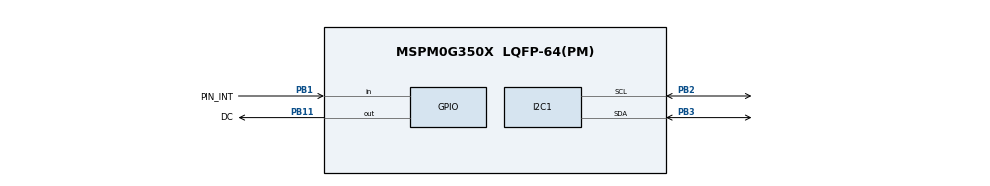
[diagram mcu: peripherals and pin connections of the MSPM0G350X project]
/**
 * @cliArgs --device "MSPM0G350X" --part "Default" --package "LQFP-64(PM)" --product "mspm0_sdk@2.05.01.00"
 * @versions {"tool":"1.24.1+4189"}
 */

/**
 * Import the modules used in this configuration.
 */
const GPIO   = scripting.addModule("/ti/driverlib/GPIO", {}, false);
const GPIO1  = GPIO.addInstance();
const GPIO2  = GPIO.addInstance();
const GPIO3  = GPIO.addInstance();
const I2C    = scripting.addModule("/ti/driverlib/I2C", {}, false);
const I2C1   = I2C.addInstance();
const SYSCTL = scripting.addModule("/ti/driverlib/SYSCTL");

/**
 * Write custom configuration values to the imported modules.
 */
GPIO1.$name                          = "GPIO_OLED";
GPIO1.port                           = "PORTB";
GPIO1.associatedPins.create(5);
GPIO1.associatedPins[0].$name        = "DC";
GPIO1.associatedPins[0].initialValue = "SET";
GPIO1.associatedPins[0].assignedPin  = "11";
GPIO1.associatedPins[0].pin.$assign  = "PB11";
GPIO1.associatedPins[1].$name        = "CS";
GPIO1.associatedPins[1].initialValue = "SET";
GPIO1.associatedPins[1].assignedPin  = "14";
GPIO1.associatedPins[2].$name        = "RST";
GPIO1.associatedPins[2].initialValue = "SET";
GPIO1.associatedPins[2].assignedPin  = "10";
GPIO1.associatedPins[3].initialValue = "SET";
GPIO1.associatedPins[3].assignedPin  = "9";
GPIO1.associatedPins[3].$name        = "SCL_OLED";
GPIO1.associatedPins[4].initialValue = "SET";
GPIO1.associatedPins[4].assignedPin  = "8";
GPIO1.associatedPins[4].$name        = "SDA_OLED";

const Board = scripting.addModule("/ti/driverlib/Board", {}, false);

GPIO2.$name                               = "GPIO_MPU6050";
GPIO2.port                                = "PORTB";
GPIO2.associatedPins[0].$name             = "PIN_INT";
GPIO2.associatedPins[0].direction         = "INPUT";
GPIO2.associatedPins[0].internalResistor  = "PULL_UP";
GPIO2.associatedPins[0].interruptEn       = true;
GPIO2.associatedPins[0].interruptPriority = "1";
GPIO2.associatedPins[0].polarity          = "FALL";
GPIO2.associatedPins[0].pin.$assign       = "PB1";

GPIO3.$name                              = "GPIO_GRAY";
GPIO3.associatedPins.create(8);
GPIO3.associatedPins[0].$name            = "PIN_0";
GPIO3.associatedPins[0].direction        = "INPUT";
GPIO3.associatedPins[0].assignedPort     = "PORTB";
GPIO3.associatedPins[0].assignedPin      = "19";
GPIO3.associatedPins[0].internalResistor = "PULL_UP";
GPIO3.associatedPins[1].$name            = "PIN_1";
GPIO3.associatedPins[1].direction        = "INPUT";
GPIO3.associatedPins[1].assignedPort     = "PORTB";
GPIO3.associatedPins[1].assignedPin      = "17";
GPIO3.associatedPins[1].internalResistor = "PULL_UP";
GPIO3.associatedPins[2].$name            = "PIN_2";
GPIO3.associatedPins[2].direction        = "INPUT";
GPIO3.associatedPins[2].assignedPort     = "PORTA";
GPIO3.associatedPins[2].assignedPin      = "16";
GPIO3.associatedPins[2].internalResistor = "PULL_UP";
GPIO3.associatedPins[3].$name            = "PIN_3";
GPIO3.associatedPins[3].direction        = "INPUT";
GPIO3.associatedPins[3].assignedPort     = "PORTA";
GPIO3.associatedPins[3].assignedPin      = "14";
GPIO3.associatedPins[3].internalResistor = "PULL_UP";
GPIO3.associatedPins[4].$name            = "PIN_4";
GPIO3.associatedPins[4].direction        = "INPUT";
GPIO3.associatedPins[4].assignedPort     = "PORTB";
GPIO3.associatedPins[4].assignedPin      = "20";
GPIO3.associatedPins[4].internalResistor = "PULL_UP";
GPIO3.associatedPins[5].$name            = "PIN_5";
GPIO3.associatedPins[5].direction        = "INPUT";
GPIO3.associatedPins[5].assignedPort     = "PORTB";
GPIO3.associatedPins[5].assignedPin      = "25";
GPIO3.associatedPins[5].internalResistor = "PULL_UP";
GPIO3.associatedPins[6].$name            = "PIN_6";
GPIO3.associatedPins[6].direction        = "INPUT";
GPIO3.associatedPins[6].assignedPort     = "PORTA";
GPIO3.associatedPins[6].assignedPin      = "25";
GPIO3.associatedPins[6].internalResistor = "PULL_UP";
GPIO3.associatedPins[7].$name            = "PIN_7";
GPIO3.associatedPins[7].direction        = "INPUT";
GPIO3.associatedPins[7].assignedPort     = "PORTA";
GPIO3.associatedPins[7].assignedPin      = "27";
GPIO3.associatedPins[7].internalResistor = "PULL_UP";

I2C1.basicEnableController             = true;
I2C1.$name                             = "I2C_MPU6050";
I2C1.peripheral.sdaPin.$assign         = "PB3";
I2C1.peripheral.sclPin.$assign         = "PB2";
I2C1.sdaPinConfig.$name                = "ti_driverlib_gpio_GPIOPinGeneric0";
I2C1.sdaPinConfig.hideOutputInversion  = scripting.forceWrite(false);
I2C1.sdaPinConfig.onlyInternalResistor = scripting.forceWrite(false);
I2C1.sdaPinConfig.passedPeripheralType = scripting.forceWrite("Digital");
I2C1.sdaPinConfig.enableConfig         = true;
I2C1.sclPinConfig.$name                = "ti_driverlib_gpio_GPIOPinGeneric1";
I2C1.sclPinConfig.hideOutputInversion  = scripting.forceWrite(false);
I2C1.sclPinConfig.onlyInternalResistor = scripting.forceWrite(false);
I2C1.sclPinConfig.passedPeripheralType = scripting.forceWrite("Digital");
I2C1.sclPinConfig.enableConfig         = true;

SYSCTL.forceDefaultClkConfig = true;

/**
 * Pinmux solution for unlocked pins/peripherals. This ensures that minor changes to the automatic solver in a future
 * version of the tool will not impact the pinmux you originally saw.  These lines can be completely deleted in order to
 * re-solve from scratch.
 */
GPIO1.associatedPins[1].pin.$suggestSolution = "PB14";
GPIO1.associatedPins[2].pin.$suggestSolution = "PB10";
GPIO1.associatedPins[3].pin.$suggestSolution = "PB9";
GPIO1.associatedPins[4].pin.$suggestSolution = "PB8";
Board.peripheral.$suggestSolution            = "DEBUGSS";
Board.peripheral.swclkPin.$suggestSolution   = "PA20";
Board.peripheral.swdioPin.$suggestSolution   = "PA19";
GPIO3.associatedPins[0].pin.$suggestSolution = "PB19";
GPIO3.associatedPins[1].pin.$suggestSolution = "PB17";
GPIO3.associatedPins[2].pin.$suggestSolution = "PA16";
GPIO3.associatedPins[3].pin.$suggestSolution = "PA14";
GPIO3.associatedPins[4].pin.$suggestSolution = "PB20";
GPIO3.associatedPins[5].pin.$suggestSolution = "PB25";
GPIO3.associatedPins[6].pin.$suggestSolution = "PA25";
GPIO3.associatedPins[7].pin.$suggestSolution = "PA27";
I2C1.peripheral.$suggestSolution             = "I2C1";
SYSCTL.peripheral.$suggestSolution           = "SYSCTL";
